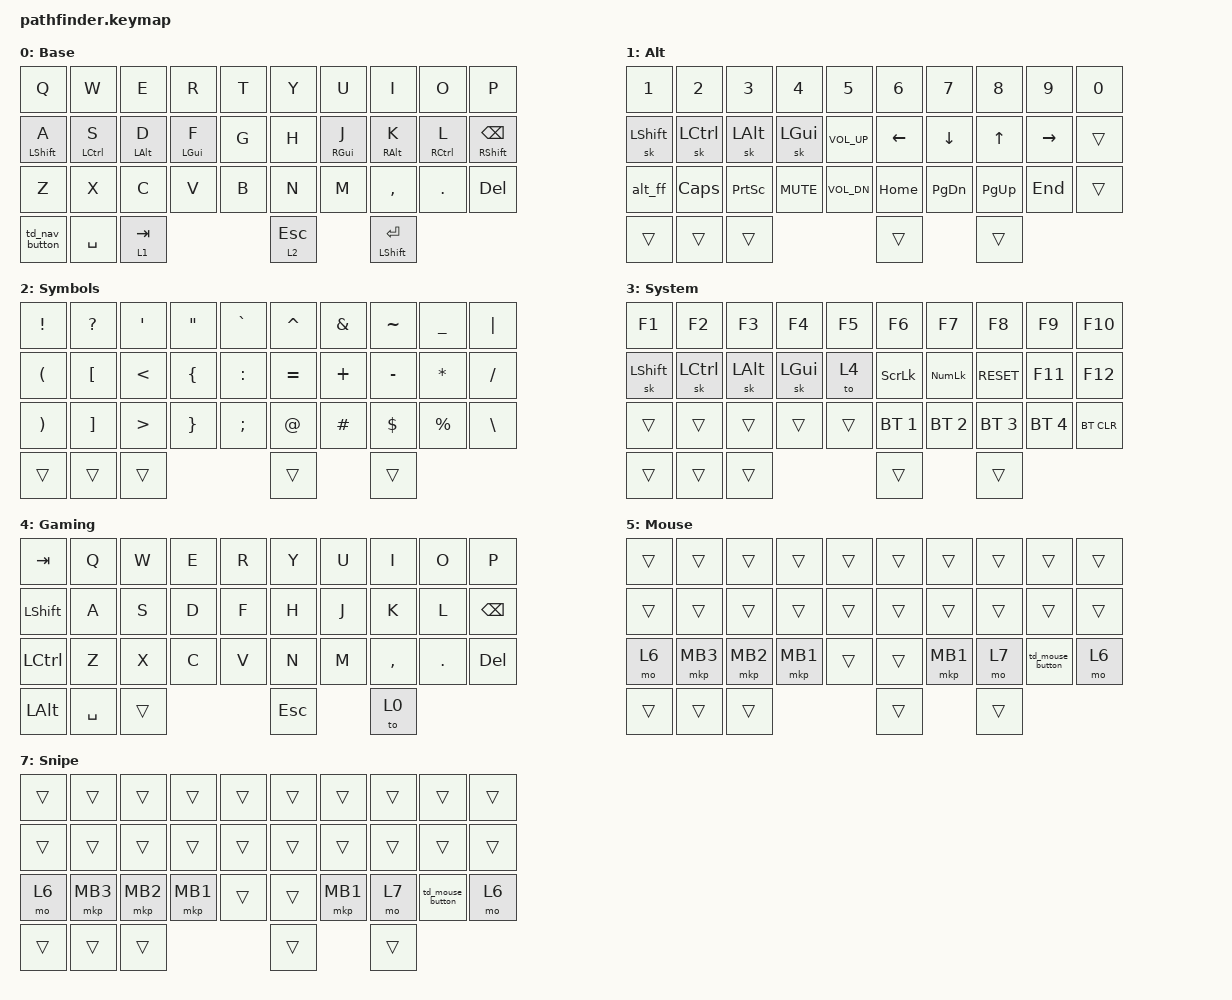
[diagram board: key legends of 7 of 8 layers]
// Includes:
#include <behaviors.dtsi>
#include <dt-bindings/zmk/keys.h>
#include <dt-bindings/zmk/mouse.h>
#include <dt-bindings/zmk/bt.h>
#include <dt-bindings/zmk/ext_power.h>
#include <dt-bindings/zmk/outputs.h>
#include "mouse.dtsi"

// Defines:
#define COMBO(NAME, BINDINGS, KEYPOS) \
combo_##NAME { \
    timeout-ms = <50>; \
    bindings = <BINDINGS>; \
    key-positions = <KEYPOS>; \
    layers = <0>; \
};
#define BASE 0
#define ALT 1
#define SYMBOLS 2
#define SYSTEM 3
#define GAMING 4
#define MOUSE 5
#define SCROLL 6
#define SNIPE 7

/ {
  macros {
    // Alt + Tab
    alt_tab: alt_tab {
      compatible = "zmk,behavior-macro";
      #binding-cells = <0>;
      bindings = <&macro_press &kp LALT>, <&macro_tap &kp TAB>, <&macro_release &kp LALT>;
    };
    // Win + Tab
    win_tab: win_tab {
      compatible = "zmk,behavior-macro";
      #binding-cells = <0>;
      bindings = <&macro_press &kp LGUI>, <&macro_tap &kp TAB>, <&macro_release &kp LGUI>;
    };
    // Win CMD Pallete
    win_cmd: win_cmd {
      compatible = "zmk,behavior-macro";
      #binding-cells = <0>;
      bindings = <&macro_press &kp LALT>, <&macro_tap &kp SPACE>, <&macro_release &kp LALT>;
    };
    // Alt + F4
    alt_ff: alt_ff {
      compatible = "zmk,behavior-macro";
      #binding-cells = <0>;
      bindings = <&macro_press &kp LALT>, <&macro_tap &kp F4>, <&macro_release &kp LALT>;
    };
    // Ctrl + Alt + Del
    ctrl_alt_del: ctrl_alt_del {
      compatible = "zmk,behavior-macro";
      #binding-cells = <0>;
      bindings = <&macro_press &kp LCTRL &kp LALT>, <&macro_tap &kp DEL>, <&macro_release &kp LCTRL &kp LALT>;
    };
    // Shift + Tab (reverse/tab back)
    shift_tab: shift_tab {
      compatible = "zmk,behavior-macro";
      #binding-cells = <0>;
      bindings = <&macro_press &kp LSHIFT>, <&macro_tap &kp TAB>, <&macro_release &kp LSHIFT>;
    };
  };

  conditional_layers {
    compatible = "zmk,conditional-layers";
    tri_layer {
      if-layers = <1 2>;
      then-layer = <3>;
    };
  };

  combos {
    compatible = "zmk,combos";

    //   0  1  2  3  4 		 5  6  7  8  9
    //  10 11 12 13 14 		15 16 17 18 19
    //  20 21 22 23 24 		25 26 27 28 29
    //        30 31 32		33 34 35

    COMBO(to_gaming,&to 4,31 32 33 34)
    COMBO(escape1,&kp ESC, 1 2)
    COMBO(escape2,&kp ESC, 7 8)
    COMBO(tab1,&kp TAB,2 3)
    COMBO(shift_tab,&shift_tab,6 7)
  };

  behaviors {
    lhm: left_homerow_mods {  
      compatible = "zmk,behavior-hold-tap";
      #binding-cells = <2>;
      flavor = "hold-preferred";
      require-prior-idle-ms = <100>;
      tapping-term-ms = <180>;
      quick-tap-ms = <200>;
      bindings = <&kp>, <&kp>;
      hold-trigger-key-positions = <16 17 18 19>; // right-hand home row mod positions
      hold-trigger-on-release;
    };
    rhm: right_homerow_mods {  
      compatible = "zmk,behavior-hold-tap";
      #binding-cells = <2>;
      flavor = "hold-preferred";
      require-prior-idle-ms = <100>;
      tapping-term-ms = <180>;
      quick-tap-ms = <200>;
      bindings = <&kp>, <&kp>;
      hold-trigger-key-positions = <10 11 12 13>; // left-hand home row mod positions
      hold-trigger-on-release;
    };
    rh_bs: right_homerow_backspace {  
      compatible = "zmk,behavior-hold-tap";
      #binding-cells = <2>;
      flavor = "hold-preferred";
      tapping-term-ms = <180>;
      quick-tap-ms = <200>; 
      bindings = <&kp>, <&kp>;
      hold-trigger-key-positions = <10 11 12 13>; // Keep left hand triggers
      hold-trigger-on-release;
      // Notice: require-prior-idle-ms is completely removed here
    };
    ent: enter_mods {  
      compatible = "zmk,behavior-hold-tap";
      #binding-cells = <2>;
      tapping-term-ms = <200>;
      quick-tap-ms = <0>;
      flavor = "hold-preferred";
      bindings = <&kp>, <&kp>;
    };
    thumb_lt: thumb_layer_tap {
      compatible = "zmk,behavior-hold-tap";
      #binding-cells = <2>;
      tapping-term-ms = <200>;
      flavor = "hold-preferred";
      bindings = <&mo>, <&kp>;
    };
    td_g0: tap_dance_gaming_0 {
      compatible = "zmk,behavior-tap-dance";
      #binding-cells = <0>;
      tapping-term-ms = <200>;
      bindings = <&kp N1>, <&kp N2>, <&kp N3>;
    };
    td_nav_button: tap_dance_nav_0 {
      compatible = "zmk,behavior-tap-dance";
      #binding-cells = <0>;
      tapping-term-ms = <200>;
      bindings = <&alt_tab>, <&win_tab>, <&win_cmd>;
    };
    td_mouse_button: tap_mouse_0 {
      compatible = "zmk,behavior-tap-dance";
      #binding-cells = <0>;
      tapping-term-ms = <200>;
      bindings = <&mkp MB2>, <&mkp MB3>;
    };

  };

  keymap {
    compatible = "zmk,keymap";

    base_layer {      
      display-name = "Base";
      bindings = <
        &kp Q           &kp W         &kp E        &kp R        &kp T      &kp Y     &kp U        &kp I        &kp O         &kp P
        &lhm LSHIFT A   &lhm LCTRL S  &lhm LALT D  &lhm LGUI F  &kp G      &kp H     &rhm RGUI J  &rhm RALT K  &rhm RCTRL L  &rh_bs RSHIFT BSPC
        &kp Z           &kp X         &kp C        &kp V        &kp B      &kp N     &kp M        &kp COMMA    &kp DOT       &kp DEL 
        &td_nav_button  &kp SPACE     &thumb_lt 1 TAB                      &thumb_lt 2 ESC  &ent LSHIFT ENTER
      > ;
    };
    alt_layer {
      display-name = "Alt";
      bindings = <
        &kp N1      &kp N2      &kp N3      &kp  N4     &kp N5         &kp N6     &kp N7     &kp N8     &kp N9      &kp N0
        &sk LSHIFT  &sk LCTRL   &sk LALT    &sk LGUI    &kp C_VOL_UP   &kp LEFT   &kp DOWN   &kp UP     &kp RIGHT   &trans      
        &alt_ff     &kp CAPS    &kp PSCRN   &kp C_MUTE  &kp C_VOL_DN   &kp HOME   &kp PG_DN  &kp PG_UP  &kp END     &trans    
        &trans      &trans      &trans                                 &trans     &trans          
      >;

    };
    symbols_layer {
      display-name = "Symbols";
      bindings = <
        &kp EXCL     &kp QMARK    &kp SQT     &kp DQT     &kp GRAVE      &kp CARET     &kp AMPS      &kp TILDE     &kp UNDER     &kp PIPE
        &kp LPAR     &kp LBKT     &kp LT      &kp LBRC    &kp COLON      &kp EQUAL     &kp PLUS      &kp MINUS     &kp STAR     &kp FSLH
        &kp RPAR     &kp RBKT     &kp GT      &kp RBRC    &kp SEMI       &kp AT        &kp POUND     &kp DLLR     &kp PRCNT     &kp BSLH
        &trans      &trans      &trans                                   &trans        &trans        
      >;

    };
    system_layer {
      display-name = "System";
      bindings = <
        &kp F1       &kp F2        &kp F3         &kp F4         &kp F5         &kp F6        &kp F7        &kp F8        &kp F9        &kp F10
        &sk LSHIFT   &sk LCTRL     &sk LALT       &sk LGUI       &to 4          &kp SLCK      &kp KP_NUM    &kp C_RESET   &kp F11       &kp F12
        &trans       &trans        &trans         &trans         &trans         &bt BT_SEL 1  &bt BT_SEL 2  &bt BT_SEL 3  &bt BT_SEL 4  &bt BT_CLR
        &trans       &trans        &trans                                       &trans        &trans         
      >;
    };
    gaming_layer {
      display-name = "Gaming";
      bindings = <
        &kp TAB    &kp Q    &kp W     &kp E     &kp R     &kp Y     &kp U     &kp I     &kp O      &kp P
        &kp LSHIFT &kp A    &kp S     &kp D     &kp F     &kp H     &kp J     &kp K     &kp L      &kp BSPC
        &kp LCTRL  &kp Z    &kp X     &kp C     &kp V     &kp N     &kp M     &kp COMMA &kp DOT    &kp DEL
        &kp LALT  &kp SPACE &trans                        &kp ESC   &to 0     
      >;
    };
mouse_layer {
      display-name = "Mouse";
      bindings = <
        &trans     &trans     &trans     &trans     &trans     &trans     &trans     &trans     &trans              &trans
        &trans     &trans     &trans     &trans     &trans     &trans     &trans     &trans     &trans              &trans
        &mo 6      &mkp MB3   &mkp MB2   &mkp MB1   &trans     &trans     &mkp MB1   &mo 7      &td_mouse_button    &mo 6     
        &trans     &trans     &trans     &trans     &trans
          >;
    };

    scroll_layer {
      display-name = "Scroll";
      bindings = <
        &trans     &trans     &trans     &trans     &trans     &trans     &trans     &trans     &trans     &trans
        &trans     &trans     &trans     &trans     &trans     &trans     &trans     &trans     &trans     &trans
        &trans     &trans     &trans     &trans     &trans     &trans     &trans     &trans     &trans     &trans
        &trans     &trans     &trans     &trans
          >;
    };
snipe_layer {
      display-name = "Snipe";
      bindings = <
        &trans     &trans     &trans     &trans     &trans     &trans     &trans     &trans     &trans             &trans
        &trans     &trans     &trans     &trans     &trans     &trans     &trans     &trans     &trans             &trans
        &mo 6      &mkp MB3   &mkp MB2   &mkp MB1   &trans     &trans     &mkp MB1   &mo 7      &td_mouse_button    &mo 6     
        &trans     &trans     &trans     &trans     &trans
          >;
    };

  };
};
